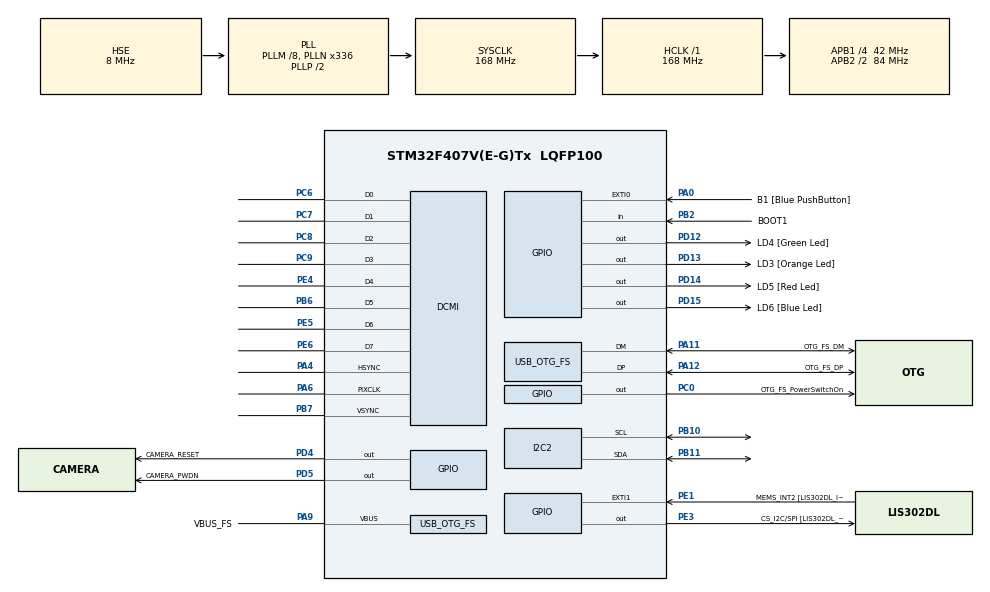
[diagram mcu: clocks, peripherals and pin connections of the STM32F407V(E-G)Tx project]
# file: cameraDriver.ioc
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DCMI.JPEGMode=DCMI_JPEG_ENABLE
DCMI.PCKPolarity=DCMI_PCKPOLARITY_RISING
DCMI.VSPolarity=DCMI_VSPOLARITY_LOW
Dma.DCMI.0.Direction=DMA_PERIPH_TO_MEMORY
Dma.DCMI.0.FIFOMode=DMA_FIFOMODE_ENABLE
Dma.DCMI.0.FIFOThreshold=DMA_FIFO_THRESHOLD_FULL
Dma.DCMI.0.Instance=DMA2_Stream1
Dma.DCMI.0.MemBurst=DMA_MBURST_SINGLE
Dma.DCMI.0.MemDataAlignment=DMA_MDATAALIGN_BYTE
Dma.DCMI.0.MemInc=DMA_MINC_ENABLE
Dma.DCMI.0.Mode=DMA_CIRCULAR
Dma.DCMI.0.PeriphBurst=DMA_PBURST_SINGLE
Dma.DCMI.0.PeriphDataAlignment=DMA_PDATAALIGN_WORD
Dma.DCMI.0.PeriphInc=DMA_PINC_DISABLE
Dma.DCMI.0.Priority=DMA_PRIORITY_VERY_HIGH
Dma.Request0=DCMI
FREERTOS.Tasks01=defaultTask,24,128,StartDefaultTask,Default,NULL,Dynamic,NULL,NULL
Mcu.Family=STM32F4
Mcu.Name=STM32F407V(E-G)Tx
Mcu.Package=LQFP100
NVIC.DCMI_IRQn=true\:5\:0\:false\:false\:true\:true\:true\:true\:true
NVIC.DMA2_Stream1_IRQn=true\:5\:0\:false\:false\:true\:true\:false\:true\:true
NVIC.OTG_FS_IRQn=true\:5\:0\:false\:false\:true\:true\:true\:true\:true
NVIC.PriorityGroup=NVIC_PRIORITYGROUP_4
PA0-WKUP.GPIO_Label=B1 [Blue PushButton]
PA0-WKUP.GPIO_ModeDefaultEXTI=GPIO_MODE_EVT_RISING
PA0-WKUP.GPIO_PuPd=GPIO_NOPULL
PA0-WKUP.Signal=GPXTI0
PA11.GPIO_Label=OTG_FS_DM
PA11.GPIO_Mode=GPIO_MODE_AF_PP
PA11.GPIO_PuPd=GPIO_NOPULL
PA11.GPIO_Speed=GPIO_SPEED_FREQ_LOW
PA11.Mode=Host_Only
PA11.Signal=USB_OTG_FS_DM
PA12.GPIO_Label=OTG_FS_DP
PA12.GPIO_Mode=GPIO_MODE_AF_PP
PA12.GPIO_PuPd=GPIO_NOPULL
PA12.GPIO_Speed=GPIO_SPEED_FREQ_LOW
PA12.Mode=Host_Only
PA12.Signal=USB_OTG_FS_DP
PA13.GPIO_Label=SWDIO
PA13.Mode=Serial_Wire
PA13.Signal=SYS_JTMS-SWDIO
PA14.GPIO_Label=SWCLK
PA14.Mode=Serial_Wire
PA14.Signal=SYS_JTCK-SWCLK
PA4.Mode=Slave_8_bits_External_Synchro
PA4.Signal=DCMI_HSYNC
PA6.Mode=Slave_8_bits_External_Synchro
PA6.Signal=DCMI_PIXCLK
PA9.GPIO_Label=VBUS_FS
PA9.GPIO_Mode=GPIO_MODE_INPUT
PA9.GPIO_PuPd=GPIO_NOPULL
PA9.Mode=Activate_VBUS
PA9.Signal=USB_OTG_FS_VBUS
PB10.Mode=I2C
PB10.Signal=I2C2_SCL
PB11.Mode=I2C
PB11.Signal=I2C2_SDA
PB2.GPIO_Label=BOOT1
PB2.GPIO_Mode=GPIO_MODE_INPUT
PB2.GPIO_PuPd=GPIO_NOPULL
PB2.Signal=GPIO_Input
PB3.GPIO_Label=SWO
PB3.Signal=SYS_JTDO-SWO
PB6.Mode=Slave_8_bits_External_Synchro
PB6.Signal=DCMI_D5
PB7.Mode=Slave_8_bits_External_Synchro
PB7.Signal=DCMI_VSYNC
PC0.GPIO_Label=OTG_FS_PowerSwitchOn
PC0.GPIO_PuPd=GPIO_NOPULL
PC0.GPIO_Speed=GPIO_SPEED_FREQ_LOW
PC0.PinState=GPIO_PIN_SET
PC0.Signal=GPIO_Output
PC14-OSC32_IN.GPIO_Label=PC14-OSC32_IN
PC14-OSC32_IN.Mode=LSE-External-Oscillator
PC14-OSC32_IN.Signal=RCC_OSC32_IN
PC15-OSC32_OUT.GPIO_Label=PC15-OSC32_OUT
PC15-OSC32_OUT.Mode=LSE-External-Oscillator
PC15-OSC32_OUT.Signal=RCC_OSC32_OUT
PC3.GPIO_Label=PDM_OUT [MP45DT02_DOUT]
PC3.GPIO_Mode=GPIO_MODE_AF_PP
PC3.GPIO_PuPd=GPIO_NOPULL
PC3.GPIO_Speed=GPIO_SPEED_FREQ_LOW
PC3.Signal=I2S2_SD
PC6.Mode=Slave_8_bits_External_Synchro
PC6.Signal=DCMI_D0
PC7.Mode=Slave_8_bits_External_Synchro
PC7.Signal=DCMI_D1
PC8.Mode=Slave_8_bits_External_Synchro
PC8.Signal=DCMI_D2
PC9.Mode=Slave_8_bits_External_Synchro
PC9.Signal=DCMI_D3
PD12.GPIO_Label=LD4 [Green Led]
PD12.GPIO_PuPd=GPIO_NOPULL
PD12.GPIO_Speed=GPIO_SPEED_FREQ_LOW
PD12.Signal=GPIO_Output
PD13.GPIO_Label=LD3 [Orange Led]
PD13.GPIO_PuPd=GPIO_NOPULL
PD13.GPIO_Speed=GPIO_SPEED_FREQ_LOW
PD13.Signal=GPIO_Output
PD14.GPIO_Label=LD5 [Red Led]
PD14.GPIO_PuPd=GPIO_NOPULL
PD14.GPIO_Speed=GPIO_SPEED_FREQ_LOW
PD14.Signal=GPIO_Output
PD15.GPIO_Label=LD6 [Blue Led]
PD15.GPIO_PuPd=GPIO_NOPULL
PD15.GPIO_Speed=GPIO_SPEED_FREQ_LOW
PD15.Signal=GPIO_Output
PD4.GPIO_Label=CAMERA_RESET
PD4.Signal=GPIO_Output
PD5.GPIO_Label=CAMERA_PWDN
PD5.Signal=GPIO_Output
PE1.GPIO_Label=MEMS_INT2 [LIS302DL_INT2]
PE1.GPIO_ModeDefaultEXTI=GPIO_MODE_EVT_RISING
PE1.GPIO_PuPd=GPIO_NOPULL
PE1.Signal=GPXTI1
PE3.GPIO_Label=CS_I2C/SPI [LIS302DL_CS_I2C/SPI]
PE3.GPIO_PuPd=GPIO_NOPULL
PE3.GPIO_Speed=GPIO_SPEED_FREQ_LOW
PE3.Signal=GPIO_Output
PE4.Mode=Slave_8_bits_External_Synchro
PE4.Signal=DCMI_D4
PE5.Mode=Slave_8_bits_External_Synchro
PE5.Signal=DCMI_D6
PE6.Mode=Slave_8_bits_External_Synchro
PE6.Signal=DCMI_D7
PH0-OSC_IN.GPIO_Label=PH0-OSC_IN
PH0-OSC_IN.Mode=HSE-External-Oscillator
PH0-OSC_IN.Signal=RCC_OSC_IN
PH1-OSC_OUT.GPIO_Label=PH1-OSC_OUT
PH1-OSC_OUT.Mode=HSE-External-Oscillator
PH1-OSC_OUT.Signal=RCC_OSC_OUT
ProjectManager.HeapSize=0x200
ProjectManager.StackSize=0x400
ProjectManager.TargetToolchain=STM32CubeIDE
RCC.48MHZClocksFreq_Value=48000000
RCC.AHBFreq_Value=168000000
RCC.APB1CLKDivider=RCC_HCLK_DIV4
RCC.APB1Freq_Value=42000000
RCC.APB1TimFreq_Value=84000000
RCC.APB2CLKDivider=RCC_HCLK_DIV2
RCC.APB2Freq_Value=84000000
RCC.APB2TimFreq_Value=168000000
RCC.CortexFreq_Value=168000000
RCC.HCLKFreq_Value=168000000
RCC.HSE_VALUE=8000000
RCC.HSI_VALUE=16000000
RCC.PLLM=8
RCC.PLLN=336
RCC.PLLQ=7
RCC.SYSCLKFreq_VALUE=168000000
RCC.SYSCLKSource=RCC_SYSCLKSOURCE_PLLCLK
RCC.VCOOutputFreq_Value=336000000
USB_HOST.BSP.number=1
USB_HOST.USBH_HandleTypeDef-CDC_FS=hUsbHostFS
USB_HOST.VirtualModeFS=Cdc
USB_HOST0.BSP.STBoard=false
USB_HOST0.BSP.api=Unknown
USB_HOST0.BSP.instance=PC0
USB_HOST0.BSP.ip=GPIO
USB_HOST0.BSP.mode=Output
USB_HOST0.BSP.name=Drive_VBUS_FS
USB_HOST0.BSP.solution=PC0
USB_OTG_FS.VirtualMode=Host_Only
USB_OTG_FS.phy_itface=HCD_PHY_EMBEDDED
VP_FREERTOS_VS_CMSIS_V2.Mode=CMSIS_V2
VP_USB_HOST_VS_USB_HOST_CDC_FS.Mode=CDC_FS
board=STM32F407G-DISC1

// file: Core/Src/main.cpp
/* USER CODE BEGIN Header */
/**
  ******************************************************************************
  * @file           : main.c
  * @brief          : Main program body
  ******************************************************************************
  * @attention
  *
  * Copyright (c) 2024 STMicroelectronics.
  * All rights reserved.
  *
  * This software is licensed under terms that can be found in the LICENSE file
  * in the root directory of this software component.
  * If no LICENSE file comes with this software, it is provided AS-IS.
  *
  ******************************************************************************
  */
/* USER CODE END Header */
#include "main.h"
#include "cmsis_os.h"
#include "usb_host.h"
#include "CameraMng.h"

DCMI_HandleTypeDef hdcmi;
DMA_HandleTypeDef hdma_dcmi;

I2C_HandleTypeDef hi2c2;

/* Definitions for defaultTask */
osThreadId_t defaultTaskHandle;
const osThreadAttr_t defaultTask_attributes = {
  .name = "defaultTask",
  .stack_size = 128 * 4,
  .priority = (osPriority_t) osPriorityNormal,
};

void SystemClock_Config(void);
static void MX_GPIO_Init(void);
static void MX_DMA_Init(void);
static void MX_DCMI_Init(void);
static void MX_I2C2_Init(void);
void StartDefaultTask(void *argument);

/* USER CODE BEGIN 0 */

using namespace Components::DataHandling;
/* USER CODE END 0 */

int main(void)
{

  /* MCU Configuration--------------------------------------------------------*/

  /* Reset of all peripherals, Initializes the Flash interface and the Systick. */
  HAL_Init();

  /* Configure the system clock */
  SystemClock_Config();

  /* Initialize all configured peripherals */
  MX_GPIO_Init();
  MX_DMA_Init();
  MX_DCMI_Init();
  MX_I2C2_Init();
  /* USER CODE BEGIN 2 */

  CameraMng cameraMng(CameraCfg{hdcmi, hdma_dcmi, hi2c2});
  cameraMng.initialization();
  cameraMng.configuration(CameraResolution::RES_320X240);

  while(1)
  {
	  cameraMng.captureScreenshot();
	  cameraMng.processCapture();
	  HAL_Delay(3000);
  }
  /* USER CODE END 2 */

  /* Init scheduler */
  osKernelInitialize();

  /* Create the thread(s) */
  /* creation of defaultTask */
  defaultTaskHandle = osThreadNew(StartDefaultTask, NULL, &defaultTask_attributes);

  /* Start scheduler */
  osKernelStart();

  /* We should never get here as control is now taken by the scheduler */
  /* Infinite loop */
  while (1)
  {

  }
}

void SystemClock_Config(void)
{
  RCC_OscInitTypeDef RCC_OscInitStruct = {0};
  RCC_ClkInitTypeDef RCC_ClkInitStruct = {0};

  /** Configure the main internal regulator output voltage
  */
  __HAL_RCC_PWR_CLK_ENABLE();
  __HAL_PWR_VOLTAGESCALING_CONFIG(PWR_REGULATOR_VOLTAGE_SCALE1);

  /** Initializes the RCC Oscillators according to the specified parameters
  * in the RCC_OscInitTypeDef structure.
  */
  RCC_OscInitStruct.OscillatorType = RCC_OSCILLATORTYPE_HSE;
  RCC_OscInitStruct.HSEState = RCC_HSE_ON;
  RCC_OscInitStruct.PLL.PLLState = RCC_PLL_ON;
  RCC_OscInitStruct.PLL.PLLSource = RCC_PLLSOURCE_HSE;
  RCC_OscInitStruct.PLL.PLLM = 8;
  RCC_OscInitStruct.PLL.PLLN = 336;
  RCC_OscInitStruct.PLL.PLLP = RCC_PLLP_DIV2;
  RCC_OscInitStruct.PLL.PLLQ = 7;
  if (HAL_RCC_OscConfig(&RCC_OscInitStruct) != HAL_OK)
  {
    Error_Handler();
  }

  /** Initializes the CPU, AHB and APB buses clocks
  */
  RCC_ClkInitStruct.ClockType = RCC_CLOCKTYPE_HCLK|RCC_CLOCKTYPE_SYSCLK
                              |RCC_CLOCKTYPE_PCLK1|RCC_CLOCKTYPE_PCLK2;
  RCC_ClkInitStruct.SYSCLKSource = RCC_SYSCLKSOURCE_PLLCLK;
  RCC_ClkInitStruct.AHBCLKDivider = RCC_SYSCLK_DIV1;
  RCC_ClkInitStruct.APB1CLKDivider = RCC_HCLK_DIV4;
  RCC_ClkInitStruct.APB2CLKDivider = RCC_HCLK_DIV2;

  if (HAL_RCC_ClockConfig(&RCC_ClkInitStruct, FLASH_LATENCY_5) != HAL_OK)
  {
    Error_Handler();
  }
}

static void MX_DCMI_Init(void)
{

  hdcmi.Instance = DCMI;
  hdcmi.Init.SynchroMode = DCMI_SYNCHRO_HARDWARE;
  hdcmi.Init.PCKPolarity = DCMI_PCKPOLARITY_RISING;
  hdcmi.Init.VSPolarity = DCMI_VSPOLARITY_LOW;
  hdcmi.Init.HSPolarity = DCMI_HSPOLARITY_LOW;
  hdcmi.Init.CaptureRate = DCMI_CR_ALL_FRAME;
  hdcmi.Init.ExtendedDataMode = DCMI_EXTEND_DATA_8B;
  hdcmi.Init.JPEGMode = DCMI_JPEG_ENABLE;
  if (HAL_DCMI_Init(&hdcmi) != HAL_OK)
  {
    Error_Handler();
  }

}

static void MX_I2C2_Init(void)
{

  hi2c2.Instance = I2C2;
  hi2c2.Init.ClockSpeed = 100000;
  hi2c2.Init.DutyCycle = I2C_DUTYCYCLE_2;
  hi2c2.Init.OwnAddress1 = 0;
  hi2c2.Init.AddressingMode = I2C_ADDRESSINGMODE_7BIT;
  hi2c2.Init.DualAddressMode = I2C_DUALADDRESS_DISABLE;
  hi2c2.Init.OwnAddress2 = 0;
  hi2c2.Init.GeneralCallMode = I2C_GENERALCALL_DISABLE;
  hi2c2.Init.NoStretchMode = I2C_NOSTRETCH_DISABLE;
  if (HAL_I2C_Init(&hi2c2) != HAL_OK)
  {
    Error_Handler();
  }

}

static void MX_DMA_Init(void)
{

  /* DMA controller clock enable */
  __HAL_RCC_DMA2_CLK_ENABLE();

  /* DMA interrupt init */
  /* DMA2_Stream1_IRQn interrupt configuration */
  HAL_NVIC_SetPriority(DMA2_Stream1_IRQn, 5, 0);
  HAL_NVIC_EnableIRQ(DMA2_Stream1_IRQn);

}

static void MX_GPIO_Init(void)
{
  GPIO_InitTypeDef GPIO_InitStruct = {0};

  /* GPIO Ports Clock Enable */
  __HAL_RCC_GPIOE_CLK_ENABLE();
  __HAL_RCC_GPIOC_CLK_ENABLE();
  __HAL_RCC_GPIOH_CLK_ENABLE();
  __HAL_RCC_GPIOA_CLK_ENABLE();
  __HAL_RCC_GPIOB_CLK_ENABLE();
  __HAL_RCC_GPIOD_CLK_ENABLE();

  /*Configure GPIO pin Output Level */
  HAL_GPIO_WritePin(CS_I2C_SPI_GPIO_Port, CS_I2C_SPI_Pin, GPIO_PIN_RESET);

  /*Configure GPIO pin Output Level */
  HAL_GPIO_WritePin(OTG_FS_PowerSwitchOn_GPIO_Port, OTG_FS_PowerSwitchOn_Pin, GPIO_PIN_SET);

  /*Configure GPIO pin Output Level */
  HAL_GPIO_WritePin(GPIOD, LD4_Pin|LD3_Pin|LD5_Pin|LD6_Pin
                          |CAMERA_RESET_Pin|CAMERA_PWDN_Pin, GPIO_PIN_RESET);

  /*Configure GPIO pin : CS_I2C_SPI_Pin */
  GPIO_InitStruct.Pin = CS_I2C_SPI_Pin;
  GPIO_InitStruct.Mode = GPIO_MODE_OUTPUT_PP;
  GPIO_InitStruct.Pull = GPIO_NOPULL;
  GPIO_InitStruct.Speed = GPIO_SPEED_FREQ_LOW;
  HAL_GPIO_Init(CS_I2C_SPI_GPIO_Port, &GPIO_InitStruct);

  /*Configure GPIO pin : OTG_FS_PowerSwitchOn_Pin */
  GPIO_InitStruct.Pin = OTG_FS_PowerSwitchOn_Pin;
  GPIO_InitStruct.Mode = GPIO_MODE_OUTPUT_PP;
  GPIO_InitStruct.Pull = GPIO_NOPULL;
  GPIO_InitStruct.Speed = GPIO_SPEED_FREQ_LOW;
  HAL_GPIO_Init(OTG_FS_PowerSwitchOn_GPIO_Port, &GPIO_InitStruct);

  /*Configure GPIO pin : PDM_OUT_Pin */
  GPIO_InitStruct.Pin = PDM_OUT_Pin;
  GPIO_InitStruct.Mode = GPIO_MODE_AF_PP;
  GPIO_InitStruct.Pull = GPIO_NOPULL;
  GPIO_InitStruct.Speed = GPIO_SPEED_FREQ_LOW;
  GPIO_InitStruct.Alternate = GPIO_AF5_SPI2;
  HAL_GPIO_Init(PDM_OUT_GPIO_Port, &GPIO_InitStruct);

  /*Configure GPIO pin : B1_Pin */
  GPIO_InitStruct.Pin = B1_Pin;
  GPIO_InitStruct.Mode = GPIO_MODE_EVT_RISING;
  GPIO_InitStruct.Pull = GPIO_NOPULL;
  HAL_GPIO_Init(B1_GPIO_Port, &GPIO_InitStruct);

  /*Configure GPIO pin : BOOT1_Pin */
  GPIO_InitStruct.Pin = BOOT1_Pin;
  GPIO_InitStruct.Mode = GPIO_MODE_INPUT;
  GPIO_InitStruct.Pull = GPIO_NOPULL;
  HAL_GPIO_Init(BOOT1_GPIO_Port, &GPIO_InitStruct);

  /*Configure GPIO pins : LD4_Pin LD3_Pin LD5_Pin LD6_Pin
                           CAMERA_RESET_Pin CAMERA_PWDN_Pin */
  GPIO_InitStruct.Pin = LD4_Pin|LD3_Pin|LD5_Pin|LD6_Pin
                          |CAMERA_RESET_Pin|CAMERA_PWDN_Pin;
  GPIO_InitStruct.Mode = GPIO_MODE_OUTPUT_PP;
  GPIO_InitStruct.Pull = GPIO_NOPULL;
  GPIO_InitStruct.Speed = GPIO_SPEED_FREQ_LOW;
  HAL_GPIO_Init(GPIOD, &GPIO_InitStruct);

  /*Configure GPIO pin : MEMS_INT2_Pin */
  GPIO_InitStruct.Pin = MEMS_INT2_Pin;
  GPIO_InitStruct.Mode = GPIO_MODE_EVT_RISING;
  GPIO_InitStruct.Pull = GPIO_NOPULL;
  HAL_GPIO_Init(MEMS_INT2_GPIO_Port, &GPIO_InitStruct);

}

void StartDefaultTask(void *argument)
{
  /* init code for USB_HOST */
  MX_USB_HOST_Init();
  for(;;)
  {
    osDelay(1);
  }
}

void Error_Handler(void)
{
  __disable_irq();
  while (1)
  {
  }
}
